# R7FA6M3AH register map
Vendor: Renesas; Series: RA6; File version: 1.2
CPU: CM4 r0p1, little endian, MPU, FPU, VTOR, 4 interrupt priority bits
Registers are 32-bit, read-write, reset 0x0 unless marked. A register's access mark holds for its fields unless they carry their own. Offsets are from the block's base; [hi:lo] are bit positions; {n}, {i} and the like mark numbered series.

## SYSTEM — System Control
Base 0x4001E000
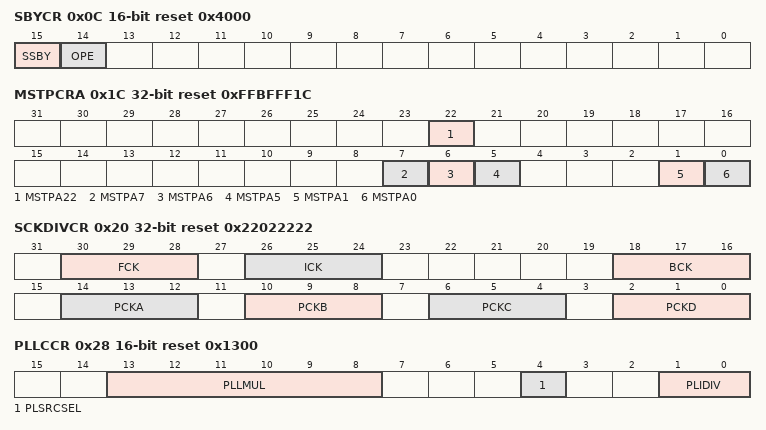
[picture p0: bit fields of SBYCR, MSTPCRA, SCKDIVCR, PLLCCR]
0x0C SBYCR 16-bit reset 0x4000 — Standby Control Register
  [15] SSBY — Software Standby
  [14] OPE — Output Port Enable
0x1C MSTPCRA reset 0xFFBFFF1C — Module Stop Control Register A
  [22] MSTPA22 — DMA Controller/Data Transfer Controller Module Stop
  [7] MSTPA7 — Standny RAM Module Stop
  [6] MSTPA6 — ECCRAM Module Stop
  [5] MSTPA5 — High,Speed RAM Module Stop
  [1] MSTPA1 — RAM1 Module Stop
  [0] MSTPA0 — RAM0 Module Stop
0x20 SCKDIVCR reset 0x22022222 — System Clock Division Control Register
  [30:28] FCK — Flash IF Clock (FCLK) Select
  [26:24] ICK — System Clock (ICLK) Select
  [18:16] BCK — External Bus Clock (BCLK) Select
  [14:12] PCKA — Peripheral Module Clock A (PCLKA) Select
  [10:8] PCKB — Peripheral Module Clock B (PCLKB) Select
  [6:4] PCKC — Peripheral Module Clock C (PCLKC) Select
  [2:0] PCKD — Peripheral Module Clock D (PCLKD) Select
0x24 SCKDIVCR2 8-bit reset 0x40 — System Clock Division Control Register 2
  [6:4] UCK — USB Clock (UCLK) Select
0x26 SCKSCR 8-bit reset 0x1 — System Clock Source Control Register
  [2:0] CKSEL — Clock Source Select
0x28 PLLCCR 16-bit reset 0x1300 — PLL Clock Control Register
  [13:8] PLLMUL range #010011..#111011 — PLL Frequency Multiplication Factor Select [PLL Frequency Multiplication Factor] = (PLLUMUL+1) / 2 Range: 0x23 - 0x3B for example 010011: x10.0 010100: x10.5 010101: x11.0 : 011100: x14.5 011101: x15.0 011110: x15.5 : 111010: x29.5 111011: x30.0
  [4] PLSRCSEL — PLL Clock Source Select
  [1:0] PLIDIV — PLL Input Frequency Division Ratio Select
0x2A PLLCR 8-bit reset 0x1 — PLL Control Register
  [0] PLLSTP — PLL Stop Control
0x30 BCKCR 8-bit — External Bus Clock Control Register
  [0] BCLKDIV — BCLK Pin Output Select
0x32 MOSCCR 8-bit reset 0x1 — Main Clock Oscillator Control Register
  [0] MOSTP — Main Clock Oscillator Stop
0x36 HOCOCR 8-bit (reset mask 0xFE) — High,Speed On,Chip Oscillator Control Register
  [0] HCSTP — HOCO Stop
0x38 MOCOCR 8-bit — Middle,Speed On,Chip Oscillator Control Register
  [0] MCSTP — MOCO Stop
0x39 FLLCR1 8-bit — FLL Control Register 1
  [0] FLLEN — FLL Enable
0x3A FLLCR2 16-bit — FLL Control Register 2
  [10:0] FLLCNTL — FLL Multiplication ControlMultiplication ratio of the FLL reference clock select
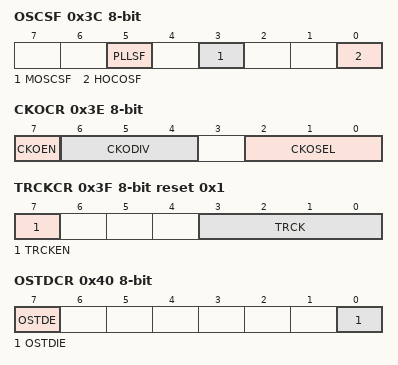
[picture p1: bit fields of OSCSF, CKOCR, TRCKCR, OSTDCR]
0x3C OSCSF 8-bit ro (reset mask 0xFE) — Oscillation Stabilization Flag Register
  [5] PLLSF — PLL Clock Oscillation Stabilization Flag
  [3] MOSCSF — Main Clock Oscillation Stabilization Flag
  [0] HOCOSF — HOCO Clock Oscillation Stabilization FlagNOTE: The HOCOSF bit value after a reset is 1 when the OFS1.HOCOEN bit is 0. It is 0 when the OFS1.HOCOEN bit is 1.
0x3E CKOCR 8-bit — Clock Out Control Register
  [7] CKOEN — Clock out enable
  [6:4] CKODIV — Clock out input frequency Division Select
  [2:0] CKOSEL — Clock out source select
0x3F TRCKCR 8-bit reset 0x1 — Trace Clock Control Register
  [7] TRCKEN — Trace Clock operating Enable
  [3:0] TRCK — Trace Clock operating frequency select
0x40 OSTDCR 8-bit — Oscillation Stop Detection Control Register
  [7] OSTDE — Oscillation Stop Detection Function Enable
  [0] OSTDIE — Oscillation Stop Detection Interrupt Enable
0x41 OSTDSR 8-bit — Oscillation Stop Detection Status Register
  [0] OSTDF write-0-clears read-modifies — Oscillation Stop Detection Flag
0x52 EBCKOCR 8-bit — External Bus Clock Output Control Register
  [0] EBCKOEN — BCLK Pin Output Control
0x53 SDCKOCR 8-bit — SDRAM Clock Output Control Register
  [0] SDCKOEN — SDCLK Pin Output Control
0x61 MOCOUTCR 8-bit — MOCO User Trimming Control Register
  [7:0] MOCOUTRM — MOCO User Trimming 1000_0000 : -128 1000_0001 : -127 1000_0010 : -126 . . . 1111_1111 : -1 0000_0000 : Center Code 0000_0001 : +1 . . . 0111_1101 : +125 0111_1110 : +126 0111_1111 : +127These bits are added to original MOCO trimming bits
0x62 HOCOUTCR 8-bit — HOCO User Trimming Control Register
  [7:0] HOCOUTRM — HOCO User Trimming 1000_0000 : -128 1000_0001 : -127 1000_0010 : -126 . . . 1111_1111 : -1 0000_0000 : Center Code 0000_0001 : +1 . . . 0111_1101 : +125 0111_1110 : +126 0111_1111 : +127These bits are added to original HOCO trimming bits
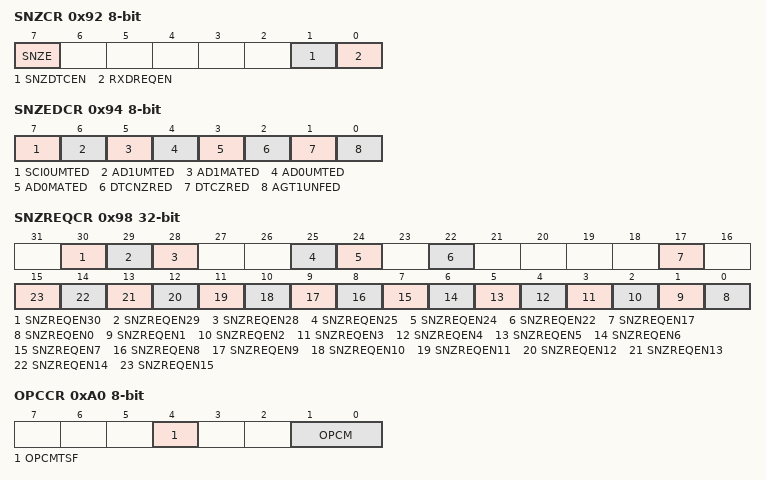
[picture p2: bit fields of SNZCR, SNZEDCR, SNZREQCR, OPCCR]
0x92 SNZCR 8-bit — Snooze Control Register
  [7] SNZE — Snooze Mode Enable
  [1] SNZDTCEN — DTC Enable in Snooze Mode
  [0] RXDREQEN — RXD0 Snooze Request Enable NOTE: Do not set to 1 other than in asynchronous mode.
0x94 SNZEDCR 8-bit — Snooze End Control Register
  [7] SCI0UMTED — SCI0 address unmatch Snooze End EnableNote: Do not set to 1 other than in asynchronous mode.
  [6] AD1UMTED — AD compare mismatch 1 Snooze End Enable
  [5] AD1MATED — AD compare match 1 Snooze End Enable
  [4] AD0UMTED — AD compare mismatch 0 Snooze End Enable
  [3] AD0MATED — AD compare match 0 Snooze End Enable
  [2] DTCNZRED — Not Last DTC transmission completion Snooze End Enable
  [1] DTCZRED — Last DTC transmission completion Snooze End Enable
  [0] AGT1UNFED — AGT1 underflow Snooze End Enable
0x98 SNZREQCR — Snooze Request Control Register
  [30] SNZREQEN30 — Snooze Request Enable 30Enable AGT1 compare match B snooze request
  [29] SNZREQEN29 — Snooze Request Enable 29Enable AGT1 compare match A snooze request
  [28] SNZREQEN28 — Snooze Request Enable 28Enable AGT1 underflow snooze request
  [25] SNZREQEN25 — Snooze Request Enable 25Enable RTC period snooze request
  [24] SNZREQEN24 — Snooze Request Enable 24Enable RTC alarm snooze request
  [22] SNZREQEN22 — Snooze Request Enable 22Enable Comparator,OC0 snooze request
  [17] SNZREQEN17 — Snooze Request Enable 17Enable KR snooze request
  [n] SNZREQEN{n} (n=0..15) — Snooze Request Enable {n}Enable IRQ{n} pin snooze request
0xA0 OPCCR 8-bit — Operating Power Control Register
  [4] OPCMTSF ro — Operating Power Control Mode Transition Status Flag
  [1:0] OPCM — Operating Power Control Mode Select
0xA2 MOSCWTCR 8-bit reset 0x5 — Main Clock Oscillator Wait Control Register
  [3:0] MSTS — Main clock oscillator wait time setting
0xA5 HOCOWTCR 8-bit reset 0x2 — High,speed on,chip oscillator wait control register
  [2:0] HSTS — HOCO wait time settingWaiting time (sec) = setting of the HSTS[2:0] bits/fLOCO(Trimmed) + 3/fLOC(Untrimmed)
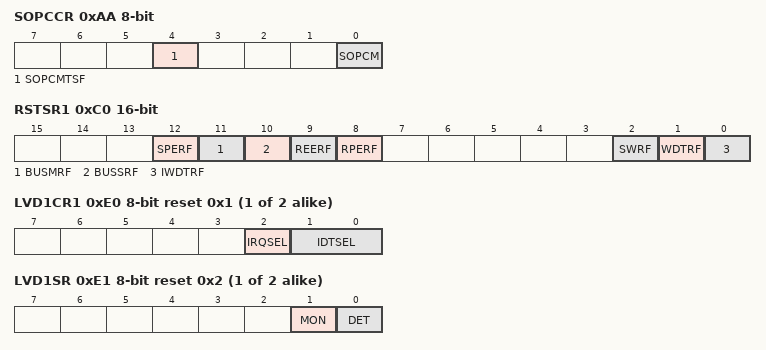
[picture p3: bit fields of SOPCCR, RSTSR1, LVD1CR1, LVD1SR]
0xAA SOPCCR 8-bit — Sub Operating Power Control Register
  [4] SOPCMTSF ro — Sub Operating Power Control Mode Transition Status Flag
  [0] SOPCM — Sub Operating Power Control Mode Select
0xC0 RSTSR1 16-bit (reset mask 0xE0F8) — Reset Status Register 1
  [12] SPERF write-0-clears read-modifies — SP Error Reset Detect FlagNOTE: Writable only to clear the flag. Confirm the value is 1 and then write 0.
  [11] BUSMRF write-0-clears read-modifies — Bus Master MPU Reset Detect FlagNOTE: Writable only to clear the flag. Confirm the value is 1 and then write 0.
  [10] BUSSRF write-0-clears read-modifies — Bus Slave MPU Reset Detect FlagNOTE: Writable only to clear the flag. Confirm the value is 1 and then write 0.
  [9] REERF write-0-clears read-modifies — RAM ECC Error Reset Detect FlagNOTE: Writable only to clear the flag. Confirm the value is 1 and then write 0.
  [8] RPERF write-0-clears read-modifies — RAM Parity Error Reset Detect FlagNOTE: Writable only to clear the flag. Confirm the value is 1 and then write 0.
  [2] SWRF write-0-clears read-modifies — Software Reset Detect FlagNOTE: Writable only to clear the flag. Confirm the value is 1 and then write 0.
  [1] WDTRF write-0-clears read-modifies — Watchdog Timer Reset Detect FlagNOTE: Writable only to clear the flag. Confirm the value is 1 and then write 0.
  [0] IWDTRF write-0-clears read-modifies — Independent Watchdog Timer Reset Detect FlagNOTE: Writable only to clear the flag. Confirm the value is 1 and then write 0.
{0xDE+2i} LVD{i}CR1 (i=1..2) 8-bit reset 0x1 — Voltage Monitor {i} Circuit Control Register 1
  [2] IRQSEL — Voltage Monitor Interrupt Type Select
  [1:0] IDTSEL — Voltage Monitor Interrupt Generation Condition Select
{0xDF+2i} LVD{i}SR (i=1..2) 8-bit reset 0x2 — Voltage Monitor {i} Circuit Status Register
  [1] MON ro — Voltage Monitor 1 Signal Monitor Flag
  [0] DET write-0-clears read-modifies — Voltage Monitor Voltage Change Detection Flag NOTE: Only 0 can be written to this bit. After writing 0 to this bit, it takes 2 system clock cycles for the bit to be read as 0.
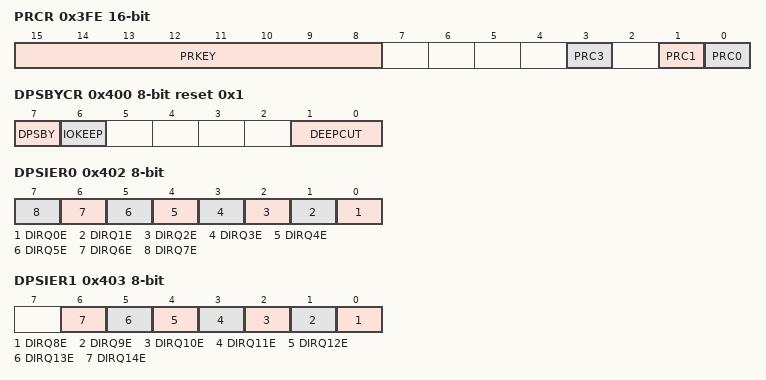
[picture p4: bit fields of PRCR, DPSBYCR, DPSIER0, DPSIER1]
0x3FE PRCR 16-bit — Protect Register
  [15:8] PRKEY wo — PRKEY Key Code
  [3] PRC3 — Enables writing to the registers related to the LVD.
  [1] PRC1 — Enables writing to the registers related to the operating modes, the low power consumption modes and the battery backup function.
  [0] PRC0 — Enables writing to the registers related to the clock generation circuit.
0x400 DPSBYCR 8-bit reset 0x1 — Deep Standby Control Register
  [7] DPSBY — Deep Software Standby
  [6] IOKEEP — I/O Port Retention
  [1:0] DEEPCUT — Power,Supply Control
0x402 DPSIER0 8-bit — Deep Standby Interrupt Enable Register 0
  [n] DIRQ{n}E (n=0..7) — IRQ{n}-DS Pin Enable
0x403 DPSIER1 8-bit — Deep Standby Interrupt Enable Register 1
  [n-8] DIRQ{n}E (n=8..14) — IRQ{n}-DS Pin Enable
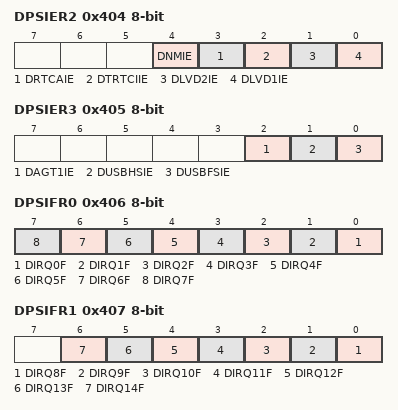
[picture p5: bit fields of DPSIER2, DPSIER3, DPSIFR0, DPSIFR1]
0x404 DPSIER2 8-bit — Deep Standby Interrupt Enable Register 2
  [4] DNMIE — NMI Pin Enable
  [3] DRTCAIE — RTC Alarm interrupt Deep Standby Cancel Signal Enable
  [2] DTRTCIIE — RTC Interval interrupt Deep Standby Cancel Signal Enable
  [1] DLVD2IE — LVD2 Deep Standby Cancel Signal Enable
  [0] DLVD1IE — LVD1 Deep Standby Cancel Signal Enable
0x405 DPSIER3 8-bit — Deep Standby Interrupt Enable Register 3
  [2] DAGT1IE — AGT1 Underflow Deep Standby Cancel Signal Enable
  [1] DUSBHSIE — USBHS Suspend/Resume Deep Standby Cancel Signal Enable
  [0] DUSBFSIE — USBFS Suspend/Resume Deep Standby Cancel Signal Enable
0x406 DPSIFR0 8-bit — Deep Standby Interrupt Flag Register 0
  [n] DIRQ{n}F write-0-clears read-modifies (n=0..7) — IRQ{n}-DS Pin Deep Standby Cancel Flag
0x407 DPSIFR1 8-bit — Deep Standby Interrupt Flag Register 1
  [n-8] DIRQ{n}F write-0-clears read-modifies (n=8..14) — IRQ{n}-DS Pin Deep Standby Cancel Flag
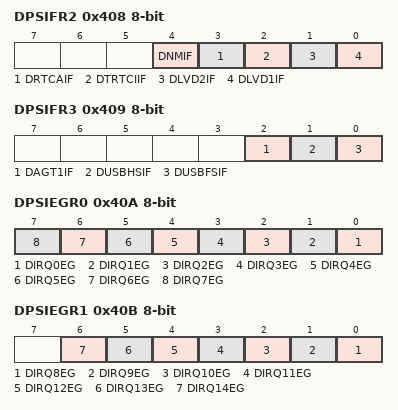
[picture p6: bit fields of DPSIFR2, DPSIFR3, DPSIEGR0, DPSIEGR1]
0x408 DPSIFR2 8-bit — Deep Standby Interrupt Flag Register 2
  [4] DNMIF write-0-clears read-modifies — NMI Pin Deep Standby Cancel Flag
  [3] DRTCAIF write-0-clears read-modifies — RTC Alarm interrupt Deep Standby Cancel Flag
  [2] DTRTCIIF write-0-clears read-modifies — RTC Interval interrupt Deep Standby Cancel Flag
  [1] DLVD2IF write-0-clears read-modifies — LVD2 Deep Standby Cancel Flag
  [0] DLVD1IF write-0-clears read-modifies — LVD1 Deep Standby Cancel Flag
0x409 DPSIFR3 8-bit — Deep Standby Interrupt Flag Register 3
  [2] DAGT1IF write-0-clears read-modifies — AGT1 Underflow Deep Standby Cancel Flag
  [1] DUSBHSIF write-0-clears read-modifies — USBHS Suspend/Resume Deep Standby Cancel Flag
  [0] DUSBFSIF write-0-clears read-modifies — USBFS Suspend/Resume Deep Standby Cancel Flag
0x40A DPSIEGR0 8-bit — Deep Standby Interrupt Edge Register 0
  [n] DIRQ{n}EG (n=0..7) — IRQ{n}-DS Pin Edge Select
0x40B DPSIEGR1 8-bit — Deep Standby Interrupt Edge Register 1
  [n-8] DIRQ{n}EG (n=8..14) — IRQ{n}-DS Pin Edge Select
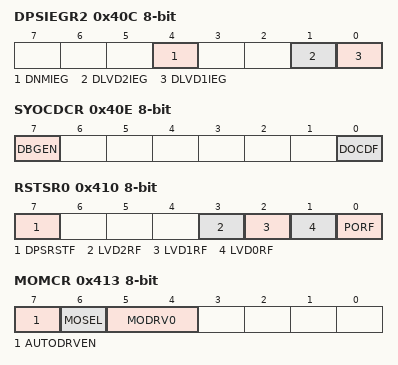
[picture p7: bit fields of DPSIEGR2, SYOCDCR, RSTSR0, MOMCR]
0x40C DPSIEGR2 8-bit — Deep Standby Interrupt Edge Register 2
  [4] DNMIEG — NMI Pin Edge Select
  [1] DLVD2IEG — LVD2 Edge Select
  [0] DLVD1IEG — LVD1 Edge Select
0x40E SYOCDCR 8-bit (reset mask 0xFE) — System Control OCD Control Register
  [7] DBGEN — Debugger Enable bit
  [0] DOCDF write-0-clears read-modifies — Deep Standby OCD flag
0x40F STCONR 8-bit reset 0xC3 — Standby Condition Register
  [1:0] STCON — SSTBY condition bit
0x410 RSTSR0 8-bit (reset mask 0x70) — Reset Status Register 0
  [7] DPSRSTF write-0-clears read-modifies — Deep Software Standby Reset FlagNOTE: Writable only to clear the flag. Confirm the value is 1 and then write 0.
  [3] LVD2RF write-0-clears read-modifies — Voltage Monitor 2 Reset Detect FlagNOTE: Writable only to clear the flag. Confirm the value is 1 and then write 0.
  [2] LVD1RF write-0-clears read-modifies — Voltage Monitor 1 Reset Detect FlagNOTE: Writable only to clear the flag. Confirm the value is 1 and then write 0.
  [1] LVD0RF write-0-clears read-modifies — Voltage Monitor 0 Reset Detect FlagNOTE: Writable only to clear the flag. Confirm the value is 1 and then write 0.
  [0] PORF write-0-clears read-modifies — Power,On Reset Detect FlagNOTE: Writable only to clear the flag. Confirm the value is 1 and then write 0.
0x411 RSTSR2 8-bit (reset mask 0xFE) — Reset Status Register 2
  [0] CWSF write-1-sets read-modifies — Cold/Warm Start Determination Flag
0x413 MOMCR 8-bit — Main Clock Oscillator Mode Oscillation Control Register
  [7] AUTODRVEN — Main Clock Oscillator Drive Capability Auto Switching Enable
  [6] MOSEL — Main Clock Oscillator Switching
  [5:4] MODRV0 — Main Clock Oscillator Drive Capability 0 Switching
0x416 FWEPROR 8-bit reset 0x2 — Flash P/E Protect Register
  [1:0] FLWE — Flash Programming and Erasure
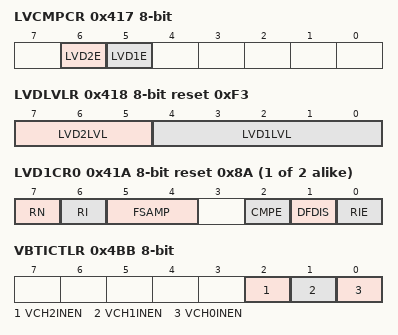
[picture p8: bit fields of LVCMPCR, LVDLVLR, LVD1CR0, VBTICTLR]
0x417 LVCMPCR 8-bit — Voltage Monitor Circuit Control Register
  [6] LVD2E — Voltage Detection 2 Enable
  [5] LVD1E — Voltage Detection 1 Enable
0x418 LVDLVLR 8-bit reset 0xF3 — Voltage Detection Level Select Register
  [7:5] LVD2LVL — Voltage Detection 2 Level Select (Standard voltage during fall in voltage)
  [4:0] LVD1LVL — Voltage Detection 1 Level Select (Standard voltage during fall in voltage)
{0x419+i} LVD{i}CR0 (i=1..2) 8-bit reset 0x8A — Voltage Monitor {i} Circuit Control Register 0
  [7] RN — Voltage Monitor Reset Negate Select
  [6] RI — Voltage Monitor Circuit Mode Select
  [5:4] FSAMP — Sampling Clock Select
  [2] CMPE — Voltage Monitor Circuit Comparison Result Output Enable
  [1] DFDIS — Voltage Monitor Digital Filter Disable Mode Select
  [0] RIE — Voltage Monitor Interrupt/Reset Enable
0x480 SOSCCR 8-bit — Sub,clock oscillator control register
  [0] SOSTP — Sub,Clock Oscillator Stop
0x481 SOMCR 8-bit (reset mask 0xFD) — Sub Clock Oscillator Mode Control Register
  [1] SODRV1 — Sub Clock Oscillator Drive Capability Switching
0x490 LOCOCR 8-bit — Low,Speed On,Chip Oscillator Control Register
  [0] LCSTP — LOCO Stop
0x492 LOCOUTCR 8-bit — LOCO User Trimming Control Register
  [7:0] LOCOUTRM — LOCO User Trimming 1000_0000 : -128 1000_0001 : -127 1000_0010 : -126 . . . 1111_1111 : -1 0000_0000 : Center Code 0000_0001 : +1 . . . 0111_1101 : +125 0111_1110 : +126 0111_1111 : +127These bits are added to original LOCO trimming bits
0x4BB VBTICTLR 8-bit (reset mask 0xF8) — VBATT Input Control Register
  [2] VCH2INEN — RTCIC2 Input Enable
  [1] VCH1INEN — RTCIC1 Input Enable
  [0] VCH0INEN — RTCIC0 Input Enable
{0x500+i} VBTBKR[{i}] (i=0..511) 8-bit reset not defined — VBATT Backup Register [{i}]
  [7:0] VBTBKR — VBTBKR is a 512-byte readable/writable register to store data powered by VBATT.The value of this register is retained even when VCC is not powered but VBATT is powered.VBTBKR is initialized by VBATT selected voltage power,on,reset.
